# STM32H745xG_CM7 register map
File version: 1.0
Registers are 32-bit, read-write, reset 0x0 unless marked. A register's access mark holds for its fields unless they carry their own. Offsets are from the block's base; [hi:lo] are bit positions; 'fields as' and 'values as' point back to an identical list.

## FLASH — FLASH Registers
Base 0x52002000
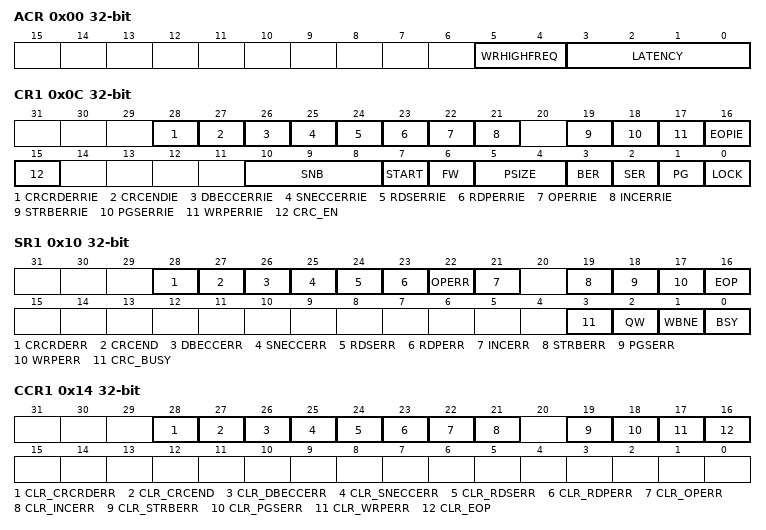
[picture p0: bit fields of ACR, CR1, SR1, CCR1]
0x00 ACR — FLASH access control register
  [5:4] WRHIGHFREQ — Flash signal delay
  [3:0] LATENCY — Read Latency
    0=FLASH Zero wait state; 1=FLASH One wait state; 2=FLASH Two wait states; 3=FLASH Three wait states; 4=FLASH Four wait states; 5=FLASH five wait state; 6=FLASH six wait state; 7=FLASH seven wait states
0x04 KEYR1 — Flash Key Register for bank1
0x08 OPTKEYR — Flash Option Key Register
0x0C CR1 — Flash Control Register for bank1
  [28] CRCRDERRIE — CRC read error interrupt enable bit
  [27] CRCENDIE — CRC end of calculation interrupt enable bit
  [26] DBECCERRIE — ECC double detection error interrupt enable bit
  [25] SNECCERRIE — ECC single correction error interrupt enable bit
  [24] RDSERRIE — Secure error interrupt enable bit
  [23] RDPERRIE — Read protection error interrupt enable bit
  [22] OPERRIE — Write/erase error interrupt enable bit
  [21] INCERRIE — Inconsistency error interrupt enable bit
  [19] STRBERRIE — Strobe error interrupt enable bit
  [18] PGSERRIE — Programming sequence error interrupt enable bit
  [17] WRPERRIE — Write protection error interrupt enable bit
  [16] EOPIE — End-of-program interrupt control bit
  [15] CRC_EN — CRC control bit
  [10:8] SNB — Sector erase selection number
  [7] START — Erase start control bit
  [6] FW — Write forcing control bit
  [5:4] PSIZE — Program size
  [3] BER — Bank erase request
  [2] SER — Sector erase request
  [1] PG — Internal buffer control bit
  [0] LOCK — Configuration lock bit
0x10 SR1 — Flash Status Register for bank1
  [28] CRCRDERR — CRC read error flag
  [27] CRCEND — CRC end of calculation flag
  [26] DBECCERR — ECC double detection error flag
  [25] SNECCERR — Single correction error flag
  [24] RDSERR — Secure error flag
  [23] RDPERR — Read protection error flag
  [22] OPERR — Write/erase error flag
  [21] INCERR — Inconsistency error flag
  [19] STRBERR — Strobe error flag
  [18] PGSERR — Programming sequence error flag
  [17] WRPERR — Write protection error flag
  [16] EOP — End-of-program flag
  [3] CRC_BUSY — CRC busy flag
  [2] QW — Wait queue flag
  [1] WBNE — Write buffer not empty flag
  [0] BSY — Busy flag
0x14 CCR1 — Flash Control Register for bank1
  [28] CLR_CRCRDERR — CRCRDERR flag clear bit
  [27] CLR_CRCEND — CRCEND flag clear bit
  [26] CLR_DBECCERR — DBECCERR flag clear bit
  [25] CLR_SNECCERR — SNECCERR flag clear bit
  [24] CLR_RDSERR — RDSERR flag clear bit
  [23] CLR_RDPERR — RDPERR flag clear bit
  [22] CLR_OPERR — OPERR flag clear bit
  [21] CLR_INCERR — INCERR flag clear bit
  [19] CLR_STRBERR — STRBERR flag clear bit
  [18] CLR_PGSERR — PGSERR flag clear bit
  [17] CLR_WRPERR — WRPERR flag clear bit
  [16] CLR_EOP — EOP flag clear bit
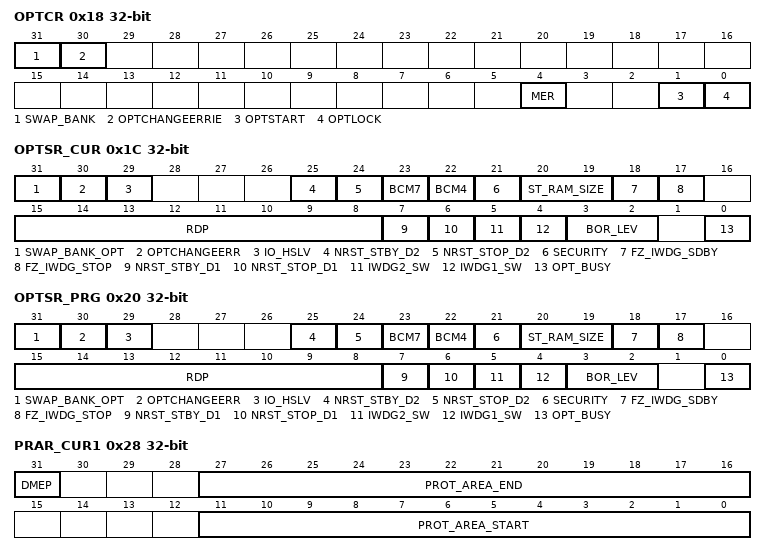
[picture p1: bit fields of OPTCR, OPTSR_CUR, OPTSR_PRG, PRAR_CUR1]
0x18 OPTCR — Flash Option Control Register
  [31] SWAP_BANK — Bank swapping option configuration bit
  [30] OPTCHANGEERRIE — Option byte change error interrupt enable bit
  [4] MER — Mass erase request
  [1] OPTSTART — Option byte start change option configuration bit
  [0] OPTLOCK — FLASH_OPTCR lock option configuration bit
0x1C OPTSR_CUR — Flash Option Status Current Register
  [31] SWAP_BANK_OPT — Bank swapping option status bit
  [30] OPTCHANGEERR — Option byte change error flag
  [29] IO_HSLV — I/O high-speed at low-voltage status bit
  [25] NRST_STBY_D2 — D2 domain DStandby entry reset option status bit
  [24] NRST_STOP_D2 — D2 domain DStop entry reset option status bit
  [23] BCM7 — Arm Cortex-M7 boot option status bit
  [22] BCM4 — Arm Cortex-M4 boot option status bit
  [21] SECURITY — Security enable option status bit
  [20:19] ST_RAM_SIZE — ST RAM size option status
  [18] FZ_IWDG_SDBY — IWDG Standby mode freeze option status bit
  [17] FZ_IWDG_STOP — IWDG Stop mode freeze option status bit
  [15:8] RDP — Readout protection level option status byte
  [7] NRST_STBY_D1 — D1 domain DStandby entry reset option status bit
  [6] NRST_STOP_D1 — D1 domain DStop entry reset option status bit
  [5] IWDG2_SW — IWDG2 control mode option status bit
  [4] IWDG1_SW — IWDG1 control mode option status bit
  [3:2] BOR_LEV — Brownout level option status bit
  [0] OPT_BUSY — Option byte change ongoing flag
0x20 OPTSR_PRG — Flash Option Status to Program Register
  fields as OPTSR_CUR
0x24 OPTCCR — Flash Option Clear Control Register
  [30] CLR_OPTCHANGEERR — OPTCHANGEERR reset bit
0x28 PRAR_CUR1 — Flash Current Protection Address Register for bank1
  [31] DMEP — PCROP protected erase enable option status bit
  [27:16] PROT_AREA_END — PCROP area end status bits
  [11:0] PROT_AREA_START — PCROP area start status bits
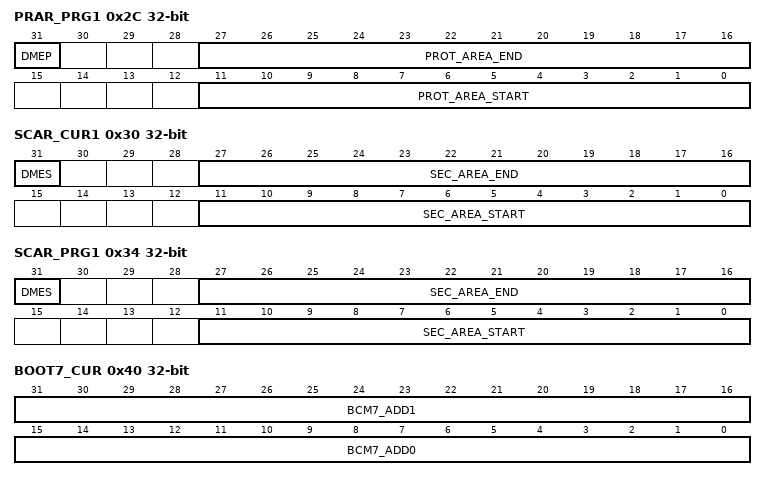
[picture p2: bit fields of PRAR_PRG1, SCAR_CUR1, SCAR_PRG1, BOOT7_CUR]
0x2C PRAR_PRG1 — Flash Protection Address to Program Register for bank1
  fields as PRAR_CUR1
0x30 SCAR_CUR1 — Flash Current Secure Address Register for bank1
  [31] DMES — Secure access protected erase enable option status bit
  [27:16] SEC_AREA_END — Secure-only area end status bits
  [11:0] SEC_AREA_START — Secure-only area start status bits
0x34 SCAR_PRG1 — Flash Secure Address to Program Register for bank1
  fields as SCAR_CUR1
0x38 WPSN_CUR1 — Flash Current Write Protection Register on bank1
  [7:0] WRPSN — Sector write protection option status byte
0x3C WPSN_PRG1 — Flash Write Protection to Program Register on bank1
  [7:0] WRPSN — Sector write protection option status byte
0x40 BOOT7_CUR — Flash Current Boot Address for Pelican Core Register
  [31:16] BCM7_ADD1 — Arm Cortex-M7 boot address 1
  [15:0] BCM7_ADD0 — Arm Cortex-M7 boot address 0
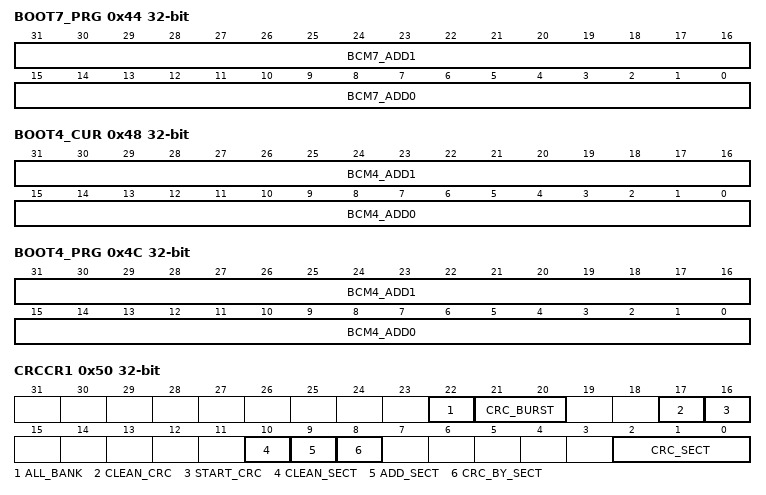
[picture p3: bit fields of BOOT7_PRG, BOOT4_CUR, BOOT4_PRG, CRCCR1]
0x44 BOOT7_PRG — Flash Boot Address to Program for Pelican Core Register
  fields as BOOT7_CUR
0x48 BOOT4_CUR — Flash Current Boot Address for M4 Core Register
  [31:16] BCM4_ADD1 — Arm Cortex-M4 boot address 1
  [15:0] BCM4_ADD0 — Arm Cortex-M4 boot address 0
0x4C BOOT4_PRG — Flash Boot Address to Program for M4 Core Register
  fields as BOOT4_CUR
0x50 CRCCR1 — Flash CRC Control register For Bank1 Register
  [22] ALL_BANK — CRC select bit
  [21:20] CRC_BURST — CRC burst size
  [17] CLEAN_CRC — CRC clear bit
  [16] START_CRC — CRC start bit
  [10] CLEAN_SECT — CRC sector list clear bit
  [9] ADD_SECT — CRC sector select bit
  [8] CRC_BY_SECT — CRC sector mode select bit
  [2:0] CRC_SECT — CRC sector number
0x54 CRCSADD1 — Flash CRC Start Address Register for Bank1
  [31:0] CRC_START_ADDR — CRC start address
0x58 CRCEADD1 — Flash CRC End Address Register for Bank1
  [31:0] CRC_END_ADDR — CRC end address
0x5C CRCDATA — Flash CRC Data Register for Bank1
  [31:0] CRC_DATA — CRC result
0x60 ECC_FA1 — Flash ECC Fail Address For Bank1 Register
  [14:0] FAIL_ECC_ADDR — ECC error address
0x104 KEYR2 — Flash Key Register for bank2
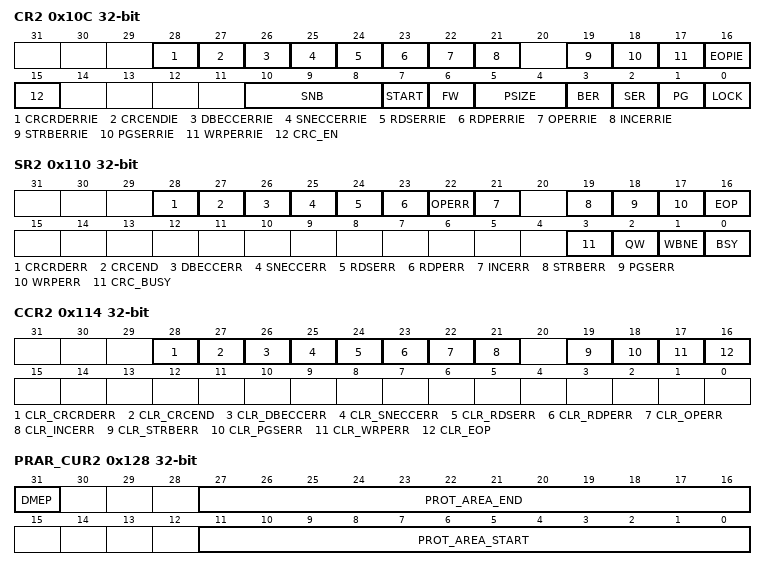
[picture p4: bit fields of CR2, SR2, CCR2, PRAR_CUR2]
0x10C CR2 — Flash Control Register for bank2
  fields as CR1
0x110 SR2 — Flash Status Register for bank2
  fields as SR1
0x114 CCR2 — Flash Status Register for bank2
  fields as CCR1
0x128 PRAR_CUR2 — Flash Current Protection Address Register for bank2
  fields as PRAR_CUR1
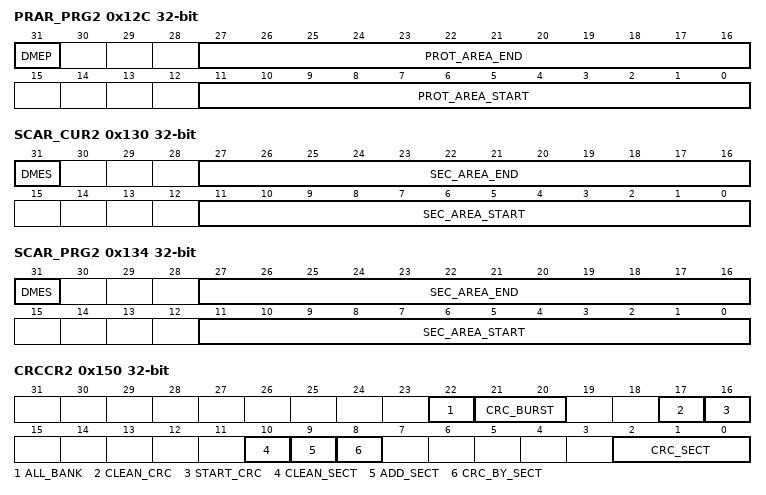
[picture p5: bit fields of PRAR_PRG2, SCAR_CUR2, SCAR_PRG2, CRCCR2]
0x12C PRAR_PRG2 — Flash Protection Address to Program Register for bank2
  fields as PRAR_CUR1
0x130 SCAR_CUR2 — Flash Current Secure Address Register for bank2
  fields as SCAR_CUR1
0x134 SCAR_PRG2 — Flash Secure Address Register for bank2
  fields as SCAR_CUR1
0x138 WPSN_CUR2 — Flash Current Write Protection Register on bank2
  [7:0] WRPSN — Sector write protection option status byte
0x13C WPSN_PRG2 — Flash Write Protection to Program Register on bank2
  [7:0] WRPSN — Sector write protection option status byte
0x150 CRCCR2 — Flash CRC Control register For Bank2 Register
  fields as CRCCR1
0x154 CRCSADD2 — Flash CRC Start Address Register for Bank2
  [31:0] CRC_START_ADDR — CRC start address
0x158 CRCEADD2 — Flash CRC End Address Register for Bank2
  [31:0] CRC_END_ADDR — CRC end address
0x15C CRCDATA2 — Flash CRC Data Register for Bank2
  [31:0] CRC_DATA — CRC result
0x160 ECC_FA2 — Flash ECC Fail Address For Bank2 Register
  [14:0] FAIL_ECC_ADDR — ECC error address
